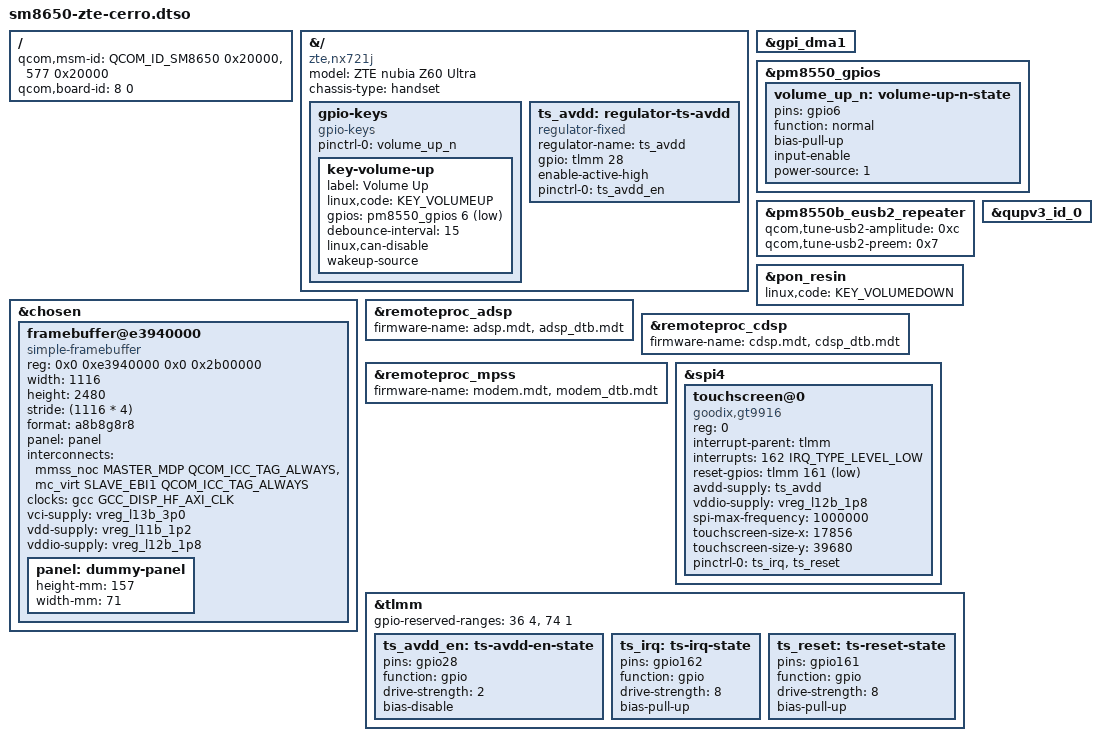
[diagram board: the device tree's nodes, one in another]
// SPDX-License-Identifier: BSD-3-Clause

/dts-v1/;
/plugin/;

#include <dt-bindings/arm/qcom,ids.h>
#include <dt-bindings/clock/qcom,sm8650-gcc.h>
#include <dt-bindings/gpio/gpio.h>
#include <dt-bindings/input/input.h>
#include <dt-bindings/interrupt-controller/irq.h>
#include <dt-bindings/interconnect/qcom,icc.h>
#include <dt-bindings/interconnect/qcom,sm8650-rpmh.h>

/ {
	qcom,msm-id = <QCOM_ID_SM8650 0x20000>, <577 0x20000>;
	qcom,board-id = <8 0>;
};

&{/} {
	model = "ZTE nubia Z60 Ultra";
	compatible = "zte,nx721j", "qcom,sm8650";
	chassis-type = "handset";

	gpio-keys {
		compatible = "gpio-keys";

		pinctrl-0 = <&volume_up_n>;
		pinctrl-names = "default";

		key-volume-up {
			label = "Volume Up";
			linux,code = <KEY_VOLUMEUP>;
			gpios = <&pm8550_gpios 6 GPIO_ACTIVE_LOW>;
			debounce-interval = <15>;
			linux,can-disable;
			wakeup-source;
		};
	};

	ts_avdd: regulator-ts-avdd {
		compatible = "regulator-fixed";

		regulator-name = "ts_avdd";

		gpio = <&tlmm 28 GPIO_ACTIVE_HIGH>;
		enable-active-high;

		pinctrl-0 = <&ts_avdd_en>;
		pinctrl-names = "default";
	};
};

&chosen {
	#address-cells = <2>;
	#size-cells = <2>;

	framebuffer@e3940000 {
		compatible = "simple-framebuffer";
		reg = <0x0 0xe3940000 0x0 0x2b00000>;
		width = <1116>;
		height = <2480>;
		stride = <(1116 * 4)>;
		format = "a8b8g8r8";
		panel = <&panel>;
		interconnects = <&mmss_noc MASTER_MDP QCOM_ICC_TAG_ALWAYS
				 &mc_virt SLAVE_EBI1 QCOM_ICC_TAG_ALWAYS>;
		clocks = <&gcc GCC_DISP_HF_AXI_CLK>;

		vci-supply = <&vreg_l13b_3p0>;
		vdd-supply = <&vreg_l11b_1p2>;
		vddio-supply = <&vreg_l12b_1p8>;

		/* Dummy panel for simple-framebuffer dimension info */
		panel: dummy-panel {
			height-mm = <157>;
			width-mm = <71>;
		};
	};
};

&gpi_dma1 {
	status = "okay";
};

&pm8550_gpios {
	volume_up_n: volume-up-n-state {
		pins = "gpio6";
		function = "normal";
		bias-pull-up;
		input-enable;
		power-source = <1>;
	};
};

&pm8550b_eusb2_repeater {
	qcom,tune-usb2-amplitude = /bits/ 8 <0xc>;
	qcom,tune-usb2-preem = /bits/ 8 <0x7>;
};

&pon_resin {
	linux,code = <KEY_VOLUMEDOWN>;

	status = "okay";
};

&qupv3_id_0 {
	status = "okay";
};

&remoteproc_adsp {
	firmware-name = "adsp.mdt", "adsp_dtb.mdt";

	status = "okay";
};

&remoteproc_cdsp {
	firmware-name = "cdsp.mdt", "cdsp_dtb.mdt";

	status = "okay";
};

&remoteproc_mpss {
	firmware-name = "modem.mdt", "modem_dtb.mdt";

	status = "okay";
};

&spi4 {
	#address-cells = <1>;
	#size-cells = <0>;

	status = "okay";

	touchscreen@0 {
		compatible = "goodix,gt9916";
		reg = <0>;

		interrupt-parent = <&tlmm>;
		interrupts = <162 IRQ_TYPE_LEVEL_LOW>;

		reset-gpios = <&tlmm 161 GPIO_ACTIVE_LOW>;

		avdd-supply = <&ts_avdd>;
		vddio-supply = <&vreg_l12b_1p8>;

		spi-max-frequency = <1000000>;

		touchscreen-size-x = <17856>;
		touchscreen-size-y = <39680>;

		pinctrl-0 = <&ts_irq>, <&ts_reset>;
		pinctrl-names = "default";
	};
};

&tlmm {
	gpio-reserved-ranges = <36 4>, <74 1>;

	ts_avdd_en: ts-avdd-en-state {
		pins = "gpio28";
		function = "gpio";
		drive-strength = <2>;
		bias-disable;
	};

	ts_irq: ts-irq-state {
		pins = "gpio162";
		function = "gpio";
		drive-strength = <8>;
		bias-pull-up;
	};

	ts_reset: ts-reset-state {
		pins = "gpio161";
		function = "gpio";
		drive-strength = <8>;
		bias-pull-up;
	};
};
